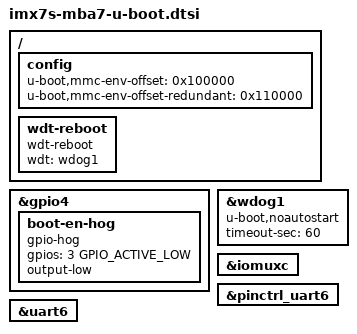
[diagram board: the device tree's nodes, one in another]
// SPDX-License-Identifier: GPL-2.0-or-later OR MIT
/*
 * Device Tree Source for TQ-Systems TQMa7S board on MBa7x carrier board.
 *
 * Copyright (C) 2025-2026 TQ-Systems GmbH <u-boot@ew.tq-group.com>,
 * D-82229 Seefeld, Germany
 * Author: Steffen Doster
 */

#include "imx7s-tqma7-u-boot.dtsi"

/ {
	config {
		u-boot,mmc-env-offset = <0x100000>;
		u-boot,mmc-env-offset-redundant = <0x110000>;
	};

	wdt-reboot {
		compatible = "wdt-reboot";
		wdt = <&wdog1>;
	};
};

&gpio4 {
	/* Deassert BOOT_EN after boot to separate BOOT_CFG circuits from LCD signals */
	boot-en-hog {
		gpio-hog;
		gpios = <3 GPIO_ACTIVE_LOW>;
		output-low;
	};
};

&wdog1 {
	u-boot,noautostart;
	timeout-sec = <60>;
};

&iomuxc {
	bootph-pre-ram;
};

&pinctrl_uart6 {
	bootph-pre-ram;
};

&uart6 {
	bootph-pre-ram;
};
